VERSION ""

NS_ :

BS_:

BU_:

BO_ 1 Outputs: 3 Vector__XXX
 SG_ ASteering : 8|12@1- (1,0) [-2048|2047] "" Vector__XXX
 SG_ BTireTempWarning : 0|1@1+ (1,0) [0|1] "" Vector__XXX

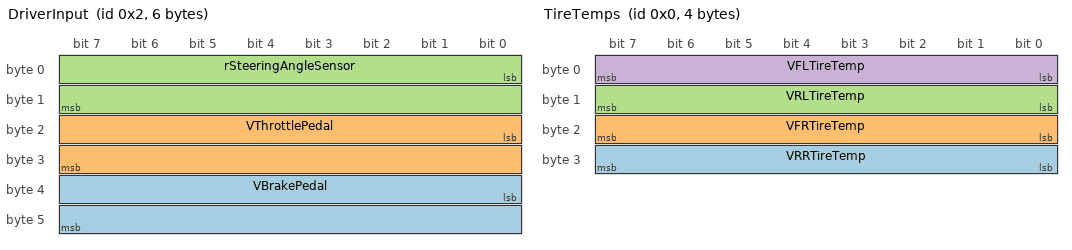
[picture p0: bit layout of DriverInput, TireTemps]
BO_ 2 DriverInput: 6 Vector__XXX
 SG_ VBrakePedal : 32|16@1+ (1,0) [0|65535] "" Vector__XXX
 SG_ VThrottlePedal : 16|16@1+ (1,0) [0|65535] "" Vector__XXX
 SG_ rSteeringAngleSensor : 0|16@1+ (1,0) [0|65535] "" Vector__XXX

BO_ 0 TireTemps: 4 Vector__XXX
 SG_ VRRTireTemp : 24|8@1+ (1,0) [0|255] "" Vector__XXX
 SG_ VFRTireTemp : 16|8@1+ (1,0) [0|255] "" Vector__XXX
 SG_ VRLTireTemp : 8|8@1+ (1,0) [0|255] "" Vector__XXX
 SG_ VFLTireTemp : 0|8@1+ (1,0) [0|255] "" Vector__XXX

BA_DEF_  "BusType" STRING ;
BA_DEF_DEF_  "BusType" "CAN";
